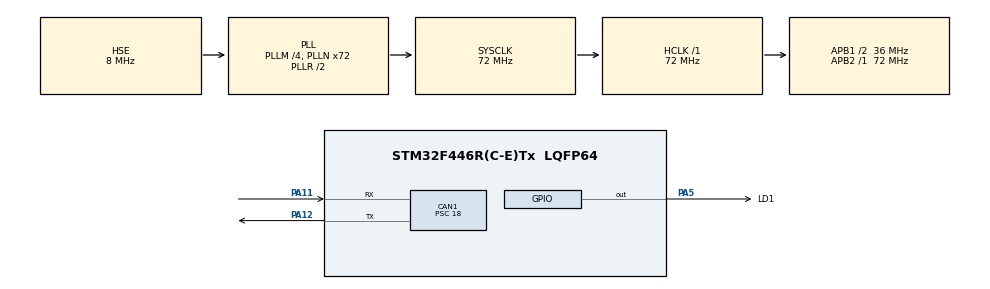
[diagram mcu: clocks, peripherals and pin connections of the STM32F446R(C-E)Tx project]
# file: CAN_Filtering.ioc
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Mcu.Family=STM32F4
RCC.PLLSourceVirtual=RCC_PLLSOURCE_HSE
PH0-OSC_IN.Signal=RCC_OSC_IN
RCC.CortexFreq_Value=72000000
CAN1.CalculateBaudRate=125000
PA11.Mode=CAN_Activate
RCC.APB1CLKDivider=RCC_HCLK_DIV2
RCC.SYSCLKSource=RCC_SYSCLKSOURCE_PLLRCLK
ProjectManager.StackSize=0x400
PA13.Signal=SYS_JTMS-SWDIO
PA12.Signal=CAN1_TX
CAN1.BS2=CAN_BS2_2TQ
CAN1.BS1=CAN_BS1_13TQ
ProjectManager.TargetToolchain=STM32CubeIDE
RCC.HCLKFreq_Value=72000000
RCC.APB2TimFreq_Value=72000000
RCC.USBFreq_Value=72000000
RCC.AHBFreq_Value=72000000
PH0-OSC_IN.Mode=HSE-External-Oscillator
PA5.Signal=GPIO_Output
RCC.HSE_VALUE=8000000
board=custom
RCC.VCOOutputFreq_Value=144000000
RCC.APB2Freq_Value=72000000
PA14.Mode=Serial_Wire
PH1-OSC_OUT.Signal=RCC_OSC_OUT
PA13.Mode=Serial_Wire
Mcu.Name=STM32F446R(C-E)Tx
PH1-OSC_OUT.Mode=HSE-External-Oscillator
RCC.SYSCLKFreq_VALUE=72000000
CAN1.Prescaler=18
Mcu.Package=LQFP64
PA12.Mode=CAN_Activate
PA5.GPIO_Label=LD1
PA11.Signal=CAN1_RX
PA14.Signal=SYS_JTCK-SWCLK
ProjectManager.HeapSize=0x200
NVIC.PriorityGroup=NVIC_PRIORITYGROUP_4
RCC.PLLM=4
RCC.PLLN=72
RCC.APB1TimFreq_Value=72000000
RCC.APB1Freq_Value=36000000
CAN1.CalculateTimeBit=8000.00
NVIC.CAN1_RX0_IRQn=true\:0\:0\:false\:false\:true\:true\:true
CAN1.CalculateTimeQuantum=500.0

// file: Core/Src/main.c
/* USER CODE BEGIN Header */
/**
  ******************************************************************************
  * @file           : main.c
  * @brief          : Main program body
  ******************************************************************************
  * @attention
  *
  * <h2><center>&copy; Copyright (c) 2021 STMicroelectronics.
  * All rights reserved.</center></h2>
  *
  * This software component is licensed by ST under BSD 3-Clause license,
  * the "License"; You may not use this file except in compliance with the
  * License. You may obtain a copy of the License at:
  *                        opensource.org/licenses/BSD-3-Clause
  *
  ******************************************************************************
  */
/* USER CODE END Header */
#include "main.h"
#include "can.h"
#include "gpio.h"

/* USER CODE BEGIN Includes */
#include "can_settings.h"
/* USER CODE END Includes */

void SystemClock_Config(void);

int main(void)
{

  /* MCU Configuration--------------------------------------------------------*/

  /* Reset of all peripherals, Initializes the Flash interface and the Systick. */
  HAL_Init();

  /* Configure the system clock */
  SystemClock_Config();

  /* Initialize all configured peripherals */
  MX_GPIO_Init();
  MX_CAN1_Init();
  /* USER CODE BEGIN 2 */
CAN_Starting(&hcan1);
uint32_t timer=HAL_GetTick();
  /* USER CODE END 2 */

  /* Infinite loop */
  /* USER CODE BEGIN WHILE */
  while (1)
  {
	  if(HAL_GetTick()-timer>200){
		  HAL_GPIO_TogglePin(LD1_GPIO_Port, LD1_Pin);
		  CAN_Transmit(0x20, 0x00, 0x01, 1, DATA);
		  timer=HAL_GetTick();
	  }
    /* USER CODE END WHILE */

  }
}

void SystemClock_Config(void)
{
  RCC_OscInitTypeDef RCC_OscInitStruct = {0};
  RCC_ClkInitTypeDef RCC_ClkInitStruct = {0};

  /** Configure the main internal regulator output voltage
  */
  __HAL_RCC_PWR_CLK_ENABLE();
  __HAL_PWR_VOLTAGESCALING_CONFIG(PWR_REGULATOR_VOLTAGE_SCALE3);
  /** Initializes the RCC Oscillators according to the specified parameters
  * in the RCC_OscInitTypeDef structure.
  */
  RCC_OscInitStruct.OscillatorType = RCC_OSCILLATORTYPE_HSE;
  RCC_OscInitStruct.HSEState = RCC_HSE_ON;
  RCC_OscInitStruct.PLL.PLLState = RCC_PLL_ON;
  RCC_OscInitStruct.PLL.PLLSource = RCC_PLLSOURCE_HSE;
  RCC_OscInitStruct.PLL.PLLM = 4;
  RCC_OscInitStruct.PLL.PLLN = 72;
  RCC_OscInitStruct.PLL.PLLP = RCC_PLLP_DIV2;
  RCC_OscInitStruct.PLL.PLLQ = 2;
  RCC_OscInitStruct.PLL.PLLR = 2;
  if (HAL_RCC_OscConfig(&RCC_OscInitStruct) != HAL_OK)
  {
    Error_Handler();
  }
  /** Initializes the CPU, AHB and APB buses clocks
  */
  RCC_ClkInitStruct.ClockType = RCC_CLOCKTYPE_HCLK|RCC_CLOCKTYPE_SYSCLK
                              |RCC_CLOCKTYPE_PCLK1|RCC_CLOCKTYPE_PCLK2;
  RCC_ClkInitStruct.SYSCLKSource = RCC_SYSCLKSOURCE_PLLRCLK;
  RCC_ClkInitStruct.AHBCLKDivider = RCC_SYSCLK_DIV1;
  RCC_ClkInitStruct.APB1CLKDivider = RCC_HCLK_DIV2;
  RCC_ClkInitStruct.APB2CLKDivider = RCC_HCLK_DIV1;

  if (HAL_RCC_ClockConfig(&RCC_ClkInitStruct, FLASH_LATENCY_2) != HAL_OK)
  {
    Error_Handler();
  }
}

void Error_Handler(void)
{
  __disable_irq();
  while (1)
  {
  }
}

/************************ (C) COPYRIGHT STMicroelectronics *****END OF FILE****/
